AUTOSAR XML (schema 4.0)
package /Battery_EV_Components
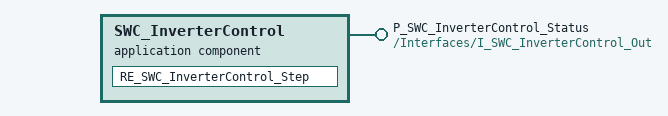
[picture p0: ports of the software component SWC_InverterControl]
  application sw component type SWC_InverterControl  # AUTOSAR Application SWC SWC_InverterControl for Battery EV Safety
    provide port P_SWC_InverterControl_Status: provided-interface=/Interfaces/I_SWC_InverterControl_Out
    behavior SWC_InverterControl_Behavior
      runnable RE_SWC_InverterControl_Step: symbol=SWC_InverterControl_Step
  sender receiver interface I_SWC_InverterControl_Out
    data DE_SWC_InverterControl_Health: type=/AUTOSAR/Platform/uint32
